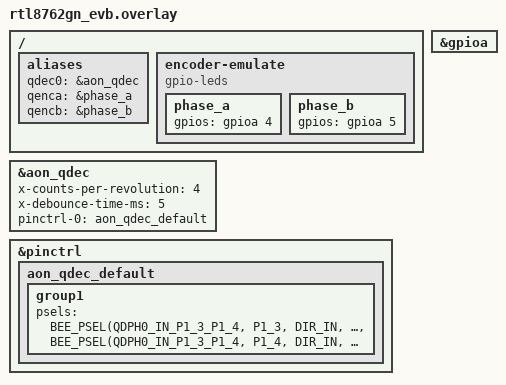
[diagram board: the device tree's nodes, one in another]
/*
 * Copyright(c) 2025, Realtek Semiconductor Corporation.
 *
 * SPDX-License-Identifier: Apache-2.0
 */

/ {
	aliases {
		qdec0 = &aon_qdec;
		qenca = &phase_a;
		qencb = &phase_b;
	};
	encoder-emulate {
		compatible = "gpio-leds";
		phase_a: phase_a {
			gpios = <&gpioa 4 GPIO_ACTIVE_HIGH>;
		};
		phase_b: phase_b {
			gpios = <&gpioa 5 GPIO_ACTIVE_HIGH>;
		};
	};
};

&gpioa {
	status = "okay";
};

&aon_qdec {
	status = "okay";
	x-counts-per-revolution = <4>;
	x-debounce-time-ms = <5>;
	pinctrl-0 = <&aon_qdec_default>;
	pinctrl-names = "default";
};

&pinctrl {
	aon_qdec_default: aon_qdec_default {
		group1 {
			psels = <BEE_PSEL(QDPH0_IN_P1_3_P1_4, P1_3, DIR_IN, DRV_LOW, PULL_UP)>,
			<BEE_PSEL(QDPH0_IN_P1_3_P1_4, P1_4, DIR_IN, DRV_LOW, PULL_UP)>;
		};
	};
};
